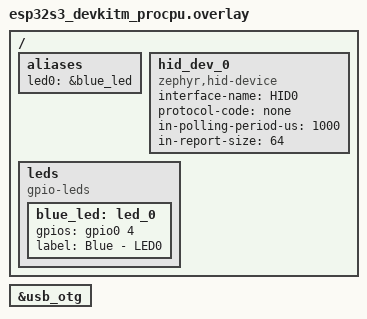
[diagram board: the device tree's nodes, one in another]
/*
 * Copyright (c) 2025 Espressif Systems (Shanghai) Co., Ltd.
 *
 * SPDX-License-Identifier: Apache-2.0
 */

/ {
	aliases {
		led0 = &blue_led;
	};

	hid_dev_0: hid_dev_0 {
		compatible = "zephyr,hid-device";
		interface-name = "HID0";
		protocol-code = "none";
		in-polling-period-us = <1000>;
		in-report-size = <64>;
	};

	leds {
		compatible = "gpio-leds";

		blue_led: led_0 {
			gpios =  <&gpio0 4 GPIO_ACTIVE_HIGH>;
			label = "Blue - LED0";
		};
	};
};

zephyr_udc0: &usb_otg {
	status = "okay";
};
